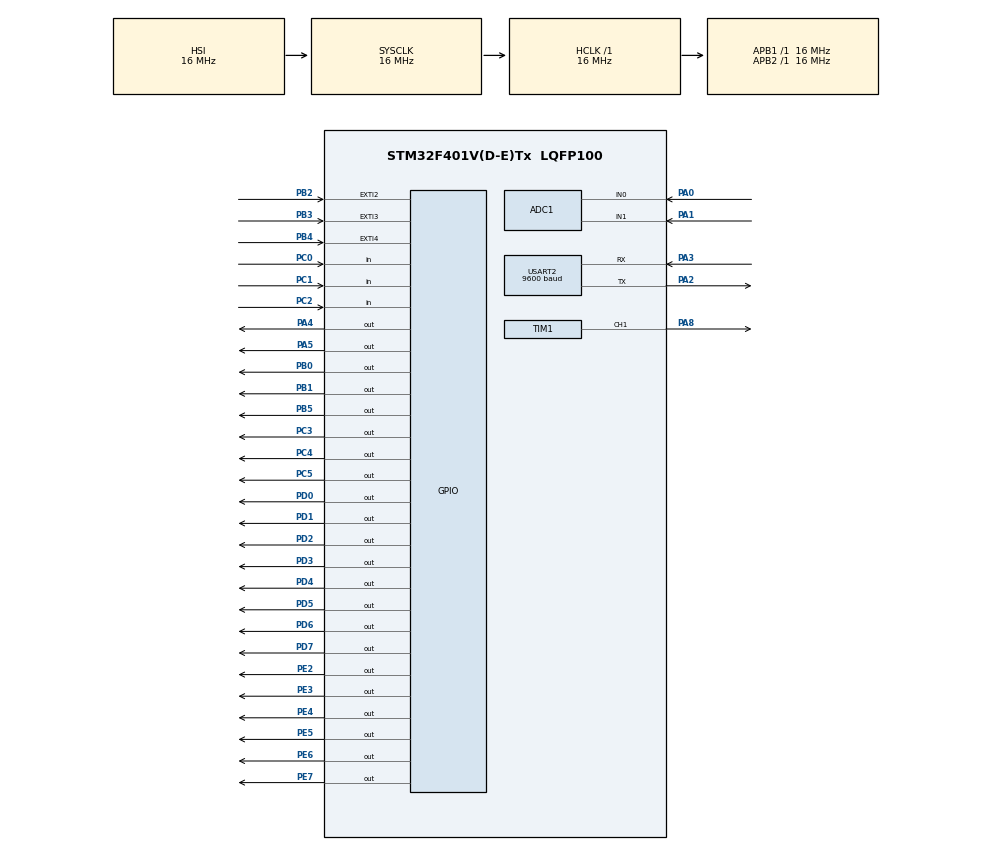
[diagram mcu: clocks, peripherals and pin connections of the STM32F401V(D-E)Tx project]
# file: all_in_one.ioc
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ADC1.Channel-0\#ChannelRegularConversion=ADC_CHANNEL_1
ADC1.NbrOfConversionFlag=1
ADC1.Rank-0\#ChannelRegularConversion=1
ADC1.SamplingTime-0\#ChannelRegularConversion=ADC_SAMPLETIME_3CYCLES
ADC1.master=1
Mcu.Family=STM32F4
Mcu.Name=STM32F401V(D-E)Tx
Mcu.Package=LQFP100
NVIC.EXTI2_IRQn=true\:0\:0\:false\:false\:true\:true\:true\:true
NVIC.EXTI3_IRQn=true\:0\:0\:false\:false\:true\:true\:true\:true
NVIC.EXTI4_IRQn=true\:0\:0\:false\:false\:true\:true\:true\:true
NVIC.PriorityGroup=NVIC_PRIORITYGROUP_4
NVIC.TIM2_IRQn=true\:0\:0\:false\:false\:true\:true\:true\:true
PA0-WKUP.Signal=ADCx_IN0
PA1.Signal=ADCx_IN1
PA13.Mode=Serial_Wire
PA13.Signal=SYS_JTMS-SWDIO
PA14.Mode=Serial_Wire
PA14.Signal=SYS_JTCK-SWCLK
PA2.Mode=Asynchronous
PA2.Signal=USART2_TX
PA3.Mode=Asynchronous
PA3.Signal=USART2_RX
PA4.Signal=GPIO_Output
PA5.Signal=GPIO_Output
PA8.Signal=S_TIM1_CH1
PB0.Signal=GPIO_Output
PB1.Signal=GPIO_Output
PB2.Signal=GPXTI2
PB3.Signal=GPXTI3
PB4.Signal=GPXTI4
PB5.Signal=GPIO_Output
PC0.Signal=GPIO_Input
PC1.Signal=GPIO_Input
PC2.Signal=GPIO_Input
PC3.Signal=GPIO_Output
PC4.Signal=GPIO_Output
PC5.Signal=GPIO_Output
PD0.Signal=GPIO_Output
PD1.Signal=GPIO_Output
PD2.Signal=GPIO_Output
PD3.Signal=GPIO_Output
PD4.Signal=GPIO_Output
PD5.Signal=GPIO_Output
PD6.Signal=GPIO_Output
PD7.Signal=GPIO_Output
PE2.Signal=GPIO_Output
PE3.Signal=GPIO_Output
PE4.Signal=GPIO_Output
PE5.Signal=GPIO_Output
PE6.Signal=GPIO_Output
PE7.Signal=GPIO_Output
ProjectManager.HeapSize=0x200
ProjectManager.StackSize=0x400
ProjectManager.TargetToolchain=STM32CubeIDE
RCC.AHBFreq_Value=16000000
RCC.APB1Freq_Value=16000000
RCC.APB2Freq_Value=16000000
RCC.CortexFreq_Value=16000000
RCC.HSE_VALUE=25000000
RCC.HSI_VALUE=16000000
RCC.LSE_VALUE=32768
RCC.SYSCLKFreq_VALUE=16000000
RCC.VCOOutputFreq_Value=192000000
SH.ADCx_IN0.0=ADC1_IN0,IN0
SH.ADCx_IN1.0=ADC1_IN1,IN1
SH.S_TIM1_CH1.0=TIM1_CH1,PWM Generation1 CH1
TIM1.Channel-PWM\ Generation1\ CH1=TIM_CHANNEL_1
TIM1.Prescaler=84
TIM2.Prescaler=8399
USART2.BaudRate=9600
USART2.VirtualMode=VM_ASYNC
VP_TIM2_VS_ClockSourceINT.Mode=Internal
board=custom

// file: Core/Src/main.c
#include "main.h"
#include "string.h"
#include <stdio.h>
#include <stdbool.h>
#include "FLASH_SECTOR_F4.h"
#include "lcd.h"
#include <inttypes.h>

#define temp_MIN 0x0807FF00
#define temp_MAX 0x0807FF20
#define alert_number 0x0807FF40

ADC_HandleTypeDef hadc1;
TIM_HandleTypeDef htim1;
TIM_HandleTypeDef htim2;
UART_HandleTypeDef huart2;

void SystemClock_Config(void);
static void MX_GPIO_Init(void);
static void MX_ADC1_Init(void);
static void MX_TIM1_Init(void);
static void MX_TIM2_Init(void);
static void MX_USART2_UART_Init(void);

extern ADC_HandleTypeDef hadc1;
extern TIM_HandleTypeDef htim1;
#define TEMP_MIN 18.0
#define TEMP_MAX 25.0

char msg[50];
uint32_t adcValue = 0;
uint8_t moteur_actif = 0;
uint8_t motor_counter = 0;
uint32_t currentTime;
uint32_t previousTime;
uint32_t led_green_Time = 0;
uint32_t BCD_Time = 0;
uint8_t counter = 0;
uint32_t start = 0;
uint16_t alert_compteur= 0;

bool led_green_state = false;
bool BCD_state = false;
bool BCD_buzz_state = false;

void write_temp_min (float temp){
	Flash_Write_NUM(temp_MIN,temp);
}
void write_temp_max (float temp){
	Flash_Write_NUM(temp_MAX,temp);
}
void write_alert_number (int num){
	Flash_Write_NUM(alert_number,num);
}

int read_alert_number (void){
	  int RxVal;
	  RxVal = Flash_Read_NUM(alert_number);
	  return RxVal;
}
float read_temp_min  (void){
	  float RxVal;
	  RxVal = Flash_Read_NUM(temp_MIN);
	  return RxVal;
}
float read_temp_max (void){
	  float RxVal;
	  RxVal = Flash_Read_NUM(temp_MAX);
	  return RxVal;
}

void setMotor(bool on) {
    if (on) {
        HAL_GPIO_WritePin(GPIOA, GPIO_PIN_4, GPIO_PIN_SET);
        __HAL_TIM_SET_COMPARE(&htim1, TIM_CHANNEL_1, 100);
    } else {
        HAL_GPIO_WritePin(GPIOA, GPIO_PIN_4, GPIO_PIN_RESET);
        __HAL_TIM_SET_COMPARE(&htim1, TIM_CHANNEL_1, 0);
    }
}

float read_temperature(void)
{
    uint32_t adc_val1 = 0;
    ADC_ChannelConfTypeDef sConfig = {0};

    sConfig.Channel = ADC_CHANNEL_1;
    sConfig.Rank = 1;
    sConfig.SamplingTime = ADC_SAMPLETIME_3CYCLES;

    if (HAL_ADC_ConfigChannel(&hadc1, &sConfig) != HAL_OK)
    {
        Error_Handler();
    }

    HAL_ADC_Start(&hadc1);
    HAL_ADC_PollForConversion(&hadc1, HAL_MAX_DELAY);
    adc_val1 = HAL_ADC_GetValue(&hadc1);
    HAL_ADC_Stop(&hadc1);

    float voltage = (adc_val1 * 5.0f) / 4095.0f;
    float temperature = voltage * 100.0f;

    return temperature;
}

void afficherLettreA(void)
{
    uint8_t segmentsActifs = 0x77;
    for (int i = 0; i < 7; i++) {
        if (segmentsActifs & (1 << i)) {
            HAL_GPIO_WritePin(GPIOD, GPIO_PIN_0 << i, GPIO_PIN_SET);
        } else {
            HAL_GPIO_WritePin(GPIOD, GPIO_PIN_0 << i, GPIO_PIN_RESET);
        }
    }
}

void eteindreAfficheur(void)
{
    for (int i = 0; i < 7; i++) {
        HAL_GPIO_WritePin(GPIOD, GPIO_PIN_0 << i, GPIO_PIN_RESET);
    }
}

uint32_t light_sensor(){
    ADC_ChannelConfTypeDef sConfig = {0};

    sConfig.Channel = ADC_CHANNEL_0;
    sConfig.Rank = 1;
    sConfig.SamplingTime = ADC_SAMPLETIME_3CYCLES;

    if (HAL_ADC_ConfigChannel(&hadc1, &sConfig) != HAL_OK)
    {
        Error_Handler();
    }

    HAL_ADC_Start(&hadc1);
    HAL_ADC_PollForConversion(&hadc1, HAL_MAX_DELAY);
    adcValue = HAL_ADC_GetValue(&hadc1);
    HAL_ADC_Stop(&hadc1);

    HAL_Delay(100);
    return adcValue;
}

int main(void)
{

  HAL_Init();
  SystemClock_Config();
  MX_GPIO_Init();
  MX_ADC1_Init();
  MX_TIM1_Init();
  MX_TIM2_Init();
  MX_USART2_UART_Init();
  HAL_TIM_PWM_Start(&htim1, TIM_CHANNEL_1);
  char msg[64];

  write_alert_number(0);
  write_temp_max(0);
  write_temp_min(999);

  LCD_Init();
  LCD_Set_Cursor(0, 0);
  LCD_Send_String("   Bienvenue");
  HAL_Delay(200);
  LCD_Init();
  LCD_Set_Cursor(0, 0);
  LCD_Send_String("                      ");
  float temps_max=0;
  float temps_min=0;

  while (1)
  {
	  HAL_Delay(100);
	  if (led_green_state){
		  LCD_Init();
		  LCD_Set_Cursor(2, 0);
		  LCD_Send_String("Personne detecté");
		  if (HAL_GetTick()-led_green_Time >= 300){
			  HAL_GPIO_TogglePin(GPIOB, GPIO_PIN_1);
			  led_green_state = false;
			  LCD_Init();
    		  LCD_Set_Cursor(0, 0);
    		  LCD_Send_String("\n                         ");
		  }
	  }

	  if(BCD_state){

		  if((HAL_GetTick() - start) > 300){
		  eteindreAfficheur();
		  }
		  if((HAL_GetTick() - start) > 600){
		  afficherLettreA();
		  start=HAL_GetTick();
		  }

	  }
  	  float temp = read_temperature();
   	  temps_max=read_temp_max();
  	  if ((temps_max)<temp){
  		  write_temp_max(temp);
  	  }
   	  temps_min=read_temp_min();
  	  if ((temps_min)>temp){
  		  write_temp_min(temp);
  	  }

  	  write_alert_number(alert_compteur);

  	  read_alert_number();
      LCD_Set_Cursor(2, 0);
      sprintf(msg, "Temperature: %.2f C\r\n", temp);
      LCD_Send_String(msg);

      if (temp >= TEMP_MAX ) {
    	  HAL_TIM_Base_Start_IT(&htim2);
      } else if (temp <= TEMP_MIN ) {
    	  HAL_TIM_Base_Stop_IT(&htim2);
    	  setMotor(false);
      }

      if(light_sensor() >= 1539){
      		  HAL_GPIO_WritePin(GPIOB, GPIO_PIN_5, GPIO_PIN_SET);
      	  }
	  else{
		  HAL_GPIO_WritePin(GPIOB, GPIO_PIN_5, GPIO_PIN_RESET);
	  }

  }
}

void SystemClock_Config(void)
{
  RCC_OscInitTypeDef RCC_OscInitStruct = {0};
  RCC_ClkInitTypeDef RCC_ClkInitStruct = {0};

  /** Configure the main internal regulator output voltage
  */
  __HAL_RCC_PWR_CLK_ENABLE();
  __HAL_PWR_VOLTAGESCALING_CONFIG(PWR_REGULATOR_VOLTAGE_SCALE2);

  /** Initializes the RCC Oscillators according to the specified parameters
  * in the RCC_OscInitTypeDef structure.
  */
  RCC_OscInitStruct.OscillatorType = RCC_OSCILLATORTYPE_HSI;
  RCC_OscInitStruct.HSIState = RCC_HSI_ON;
  RCC_OscInitStruct.HSICalibrationValue = RCC_HSICALIBRATION_DEFAULT;
  RCC_OscInitStruct.PLL.PLLState = RCC_PLL_NONE;
  if (HAL_RCC_OscConfig(&RCC_OscInitStruct) != HAL_OK)
  {
    Error_Handler();
  }

  /** Initializes the CPU, AHB and APB buses clocks
  */
  RCC_ClkInitStruct.ClockType = RCC_CLOCKTYPE_HCLK|RCC_CLOCKTYPE_SYSCLK
                              |RCC_CLOCKTYPE_PCLK1|RCC_CLOCKTYPE_PCLK2;
  RCC_ClkInitStruct.SYSCLKSource = RCC_SYSCLKSOURCE_HSI;
  RCC_ClkInitStruct.AHBCLKDivider = RCC_SYSCLK_DIV1;
  RCC_ClkInitStruct.APB1CLKDivider = RCC_HCLK_DIV1;
  RCC_ClkInitStruct.APB2CLKDivider = RCC_HCLK_DIV1;

  if (HAL_RCC_ClockConfig(&RCC_ClkInitStruct, FLASH_LATENCY_0) != HAL_OK)
  {
    Error_Handler();
  }
}

static void MX_ADC1_Init(void)
{
  ADC_ChannelConfTypeDef sConfig = {0};

  hadc1.Instance = ADC1;
  hadc1.Init.ClockPrescaler = ADC_CLOCK_SYNC_PCLK_DIV2;
  hadc1.Init.Resolution = ADC_RESOLUTION_12B;
  hadc1.Init.ScanConvMode = ENABLE;
  hadc1.Init.ContinuousConvMode = DISABLE;
  hadc1.Init.DiscontinuousConvMode = DISABLE;
  hadc1.Init.ExternalTrigConvEdge = ADC_EXTERNALTRIGCONVEDGE_NONE;
  hadc1.Init.ExternalTrigConv = ADC_SOFTWARE_START;
  hadc1.Init.DataAlign = ADC_DATAALIGN_RIGHT;
  hadc1.Init.NbrOfConversion = 2;
  hadc1.Init.DMAContinuousRequests = DISABLE;
  hadc1.Init.EOCSelection = ADC_EOC_SINGLE_CONV;
  if (HAL_ADC_Init(&hadc1) != HAL_OK)
  {
    Error_Handler();
  }

  /** Configure for the selected ADC regular channel its corresponding rank in the sequencer and its sample time.
  */
  // Channel 0 - Light Sensor (PA0)
  sConfig.Channel = ADC_CHANNEL_0;
  sConfig.Rank = 1;
  sConfig.SamplingTime = ADC_SAMPLETIME_3CYCLES;
  if (HAL_ADC_ConfigChannel(&hadc1, &sConfig) != HAL_OK)
  {
      Error_Handler();
  }

  // Channel 1 - Temperature Sensor (PA1)
  sConfig.Channel = ADC_CHANNEL_1;
  sConfig.Rank = 2;
  sConfig.SamplingTime = ADC_SAMPLETIME_3CYCLES;
  if (HAL_ADC_ConfigChannel(&hadc1, &sConfig) != HAL_OK)
  {
      Error_Handler();
  }

}

static void MX_TIM1_Init(void)
{

  TIM_MasterConfigTypeDef sMasterConfig = {0};
  TIM_OC_InitTypeDef sConfigOC = {0};
  TIM_BreakDeadTimeConfigTypeDef sBreakDeadTimeConfig = {0};

  htim1.Instance = TIM1;
  htim1.Init.Prescaler = 84;
  htim1.Init.CounterMode = TIM_COUNTERMODE_UP;
  htim1.Init.Period = 65535;
  htim1.Init.ClockDivision = TIM_CLOCKDIVISION_DIV1;
  htim1.Init.RepetitionCounter = 0;
  htim1.Init.AutoReloadPreload = TIM_AUTORELOAD_PRELOAD_DISABLE;
  if (HAL_TIM_PWM_Init(&htim1) != HAL_OK)
  {
    Error_Handler();
  }
  sMasterConfig.MasterOutputTrigger = TIM_TRGO_RESET;
  sMasterConfig.MasterSlaveMode = TIM_MASTERSLAVEMODE_DISABLE;
  if (HAL_TIMEx_MasterConfigSynchronization(&htim1, &sMasterConfig) != HAL_OK)
  {
    Error_Handler();
  }
  sConfigOC.OCMode = TIM_OCMODE_PWM1;
  sConfigOC.Pulse = 0;
  sConfigOC.OCPolarity = TIM_OCPOLARITY_HIGH;
  sConfigOC.OCNPolarity = TIM_OCNPOLARITY_HIGH;
  sConfigOC.OCFastMode = TIM_OCFAST_DISABLE;
  sConfigOC.OCIdleState = TIM_OCIDLESTATE_RESET;
  sConfigOC.OCNIdleState = TIM_OCNIDLESTATE_RESET;
  if (HAL_TIM_PWM_ConfigChannel(&htim1, &sConfigOC, TIM_CHANNEL_1) != HAL_OK)
  {
    Error_Handler();
  }
  sBreakDeadTimeConfig.OffStateRunMode = TIM_OSSR_DISABLE;
  sBreakDeadTimeConfig.OffStateIDLEMode = TIM_OSSI_DISABLE;
  sBreakDeadTimeConfig.LockLevel = TIM_LOCKLEVEL_OFF;
  sBreakDeadTimeConfig.DeadTime = 0;
  sBreakDeadTimeConfig.BreakState = TIM_BREAK_DISABLE;
  sBreakDeadTimeConfig.BreakPolarity = TIM_BREAKPOLARITY_HIGH;
  sBreakDeadTimeConfig.AutomaticOutput = TIM_AUTOMATICOUTPUT_DISABLE;
  if (HAL_TIMEx_ConfigBreakDeadTime(&htim1, &sBreakDeadTimeConfig) != HAL_OK)
  {
    Error_Handler();
  }

  HAL_TIM_MspPostInit(&htim1);
}

static void MX_TIM2_Init(void)
{

  TIM_ClockConfigTypeDef sClockSourceConfig = {0};
  TIM_MasterConfigTypeDef sMasterConfig = {0};

  htim2.Instance = TIM2;
  htim2.Init.Prescaler = 8399;
  htim2.Init.CounterMode = TIM_COUNTERMODE_UP;
  htim2.Init.Period = 999;
  htim2.Init.ClockDivision = TIM_CLOCKDIVISION_DIV1;
  htim2.Init.AutoReloadPreload = TIM_AUTORELOAD_PRELOAD_DISABLE;
  if (HAL_TIM_Base_Init(&htim2) != HAL_OK)
  {
    Error_Handler();
  }
  sClockSourceConfig.ClockSource = TIM_CLOCKSOURCE_INTERNAL;
  if (HAL_TIM_ConfigClockSource(&htim2, &sClockSourceConfig) != HAL_OK)
  {
    Error_Handler();
  }
  sMasterConfig.MasterOutputTrigger = TIM_TRGO_RESET;
  sMasterConfig.MasterSlaveMode = TIM_MASTERSLAVEMODE_DISABLE;
  if (HAL_TIMEx_MasterConfigSynchronization(&htim2, &sMasterConfig) != HAL_OK)
  {
    Error_Handler();
  }
}

static void MX_USART2_UART_Init(void)
{

  huart2.Instance = USART2;
  huart2.Init.BaudRate = 9600;
  huart2.Init.WordLength = UART_WORDLENGTH_8B;
  huart2.Init.StopBits = UART_STOPBITS_1;
  huart2.Init.Parity = UART_PARITY_NONE;
  huart2.Init.Mode = UART_MODE_TX_RX;
  huart2.Init.HwFlowCtl = UART_HWCONTROL_NONE;
  huart2.Init.OverSampling = UART_OVERSAMPLING_16;
  if (HAL_UART_Init(&huart2) != HAL_OK)
  {
    Error_Handler();
  }

}

static void MX_GPIO_Init(void)
{
  GPIO_InitTypeDef GPIO_InitStruct = {0};

  __HAL_RCC_GPIOE_CLK_ENABLE();
  __HAL_RCC_GPIOC_CLK_ENABLE();
  __HAL_RCC_GPIOA_CLK_ENABLE();
  __HAL_RCC_GPIOB_CLK_ENABLE();
  __HAL_RCC_GPIOD_CLK_ENABLE();

  /*Configure GPIO pin Output Level */
  HAL_GPIO_WritePin(GPIOE, GPIO_PIN_2|GPIO_PIN_3|GPIO_PIN_4|GPIO_PIN_5
                          |GPIO_PIN_6|GPIO_PIN_7, GPIO_PIN_RESET);

  /*Configure GPIO pin Output Level */
  HAL_GPIO_WritePin(GPIOC, GPIO_PIN_3|GPIO_PIN_4|GPIO_PIN_5, GPIO_PIN_RESET);

  /*Configure GPIO pin Output Level */
  HAL_GPIO_WritePin(GPIOA, GPIO_PIN_4|GPIO_PIN_5, GPIO_PIN_RESET);

  /*Configure GPIO pin Output Level */
  HAL_GPIO_WritePin(GPIOB, GPIO_PIN_0|GPIO_PIN_1|GPIO_PIN_5, GPIO_PIN_RESET);

  /*Configure GPIO pin Output Level */
  HAL_GPIO_WritePin(GPIOD, GPIO_PIN_0|GPIO_PIN_1|GPIO_PIN_2|GPIO_PIN_3
                          |GPIO_PIN_4|GPIO_PIN_5|GPIO_PIN_6|GPIO_PIN_7, GPIO_PIN_RESET);

  /*Configure GPIO pins : PE2 PE3 PE4 PE5
                           PE6 PE7 */
  GPIO_InitStruct.Pin = GPIO_PIN_2|GPIO_PIN_3|GPIO_PIN_4|GPIO_PIN_5
                          |GPIO_PIN_6|GPIO_PIN_7;
  GPIO_InitStruct.Mode = GPIO_MODE_OUTPUT_PP;
  GPIO_InitStruct.Pull = GPIO_NOPULL;
  GPIO_InitStruct.Speed = GPIO_SPEED_FREQ_LOW;
  HAL_GPIO_Init(GPIOE, &GPIO_InitStruct);

  /*Configure GPIO pins : PC0 PC1 PC2 */
  GPIO_InitStruct.Pin = GPIO_PIN_0|GPIO_PIN_1|GPIO_PIN_2;
  GPIO_InitStruct.Mode = GPIO_MODE_INPUT;
  GPIO_InitStruct.Pull = GPIO_NOPULL;
  HAL_GPIO_Init(GPIOC, &GPIO_InitStruct);

  /*Configure GPIO pins : PC3 PC4 PC5 */
  GPIO_InitStruct.Pin = GPIO_PIN_3|GPIO_PIN_4|GPIO_PIN_5;
  GPIO_InitStruct.Mode = GPIO_MODE_OUTPUT_PP;
  GPIO_InitStruct.Pull = GPIO_NOPULL;
  GPIO_InitStruct.Speed = GPIO_SPEED_FREQ_LOW;
  HAL_GPIO_Init(GPIOC, &GPIO_InitStruct);

  /*Configure GPIO pins : PB2 PB3 PB4 */
  GPIO_InitStruct.Pin = GPIO_PIN_2|GPIO_PIN_3|GPIO_PIN_4;
  GPIO_InitStruct.Mode = GPIO_MODE_IT_RISING;
  GPIO_InitStruct.Pull = GPIO_NOPULL;
  HAL_GPIO_Init(GPIOB, &GPIO_InitStruct);

  /*Configure GPIO pins : PA4 PA5 */
  GPIO_InitStruct.Pin = GPIO_PIN_4|GPIO_PIN_5;
  GPIO_InitStruct.Mode = GPIO_MODE_OUTPUT_PP;
  GPIO_InitStruct.Pull = GPIO_NOPULL;
  GPIO_InitStruct.Speed = GPIO_SPEED_FREQ_LOW;
  HAL_GPIO_Init(GPIOA, &GPIO_InitStruct);

  /*Configure GPIO pins : PB0 PB1 PB5 */
  GPIO_InitStruct.Pin = GPIO_PIN_0|GPIO_PIN_1|GPIO_PIN_5;
  GPIO_InitStruct.Mode = GPIO_MODE_OUTPUT_PP;
  GPIO_InitStruct.Pull = GPIO_NOPULL;
  GPIO_InitStruct.Speed = GPIO_SPEED_FREQ_LOW;
  HAL_GPIO_Init(GPIOB, &GPIO_InitStruct);

  /*Configure GPIO pins : PD0 PD1 PD2 PD3
                           PD4 PD5 PD6 PD7 */
  GPIO_InitStruct.Pin = GPIO_PIN_0|GPIO_PIN_1|GPIO_PIN_2|GPIO_PIN_3
                          |GPIO_PIN_4|GPIO_PIN_5|GPIO_PIN_6|GPIO_PIN_7;
  GPIO_InitStruct.Mode = GPIO_MODE_OUTPUT_PP;
  GPIO_InitStruct.Pull = GPIO_NOPULL;
  GPIO_InitStruct.Speed = GPIO_SPEED_FREQ_LOW;
  HAL_GPIO_Init(GPIOD, &GPIO_InitStruct);

  /* USER CODE BEGIN MX_GPIO_Init_2 */
  /* EXTI interrupt init*/
  HAL_NVIC_SetPriority(EXTI2_IRQn, 0, 0);
  HAL_NVIC_EnableIRQ(EXTI2_IRQn);

  HAL_NVIC_SetPriority(EXTI3_IRQn, 0, 0);
  HAL_NVIC_EnableIRQ(EXTI3_IRQn);

  HAL_NVIC_SetPriority(EXTI4_IRQn, 0, 0);
  HAL_NVIC_EnableIRQ(EXTI4_IRQn);
  /* USER CODE END MX_GPIO_Init_2 */
}

void HAL_GPIO_EXTI_Callback(uint16_t GPIO_Pin)
{
  /* Prevent unused argument(s) compilation warning */
  UNUSED(GPIO_Pin);
  /* NOTE: This function Should not be modified, when the callback is needed,
           the HAL_GPIO_EXTI_Callback could be implemented in the user file
   */

  	  currentTime = HAL_GetTick();
  	  // debounce for 5 ms
  	  if (currentTime - previousTime < 5) return;

      switch (GPIO_Pin)
      {

      	  case GPIO_PIN_2:

			  HAL_GPIO_TogglePin(GPIOD, GPIO_PIN_7);

			  afficherLettreA();
			  alert_compteur++;
			  BCD_state = !BCD_state;
			  if(!BCD_state){
				  eteindreAfficheur();
			  }

			  start = HAL_GetTick();
			  break;

          case GPIO_PIN_3:
        	  if(counter > 0){
        		  HAL_GPIO_WritePin(GPIOB, GPIO_PIN_0, GPIO_PIN_RESET);

        		  HAL_GPIO_TogglePin(GPIOB, GPIO_PIN_1);
        		  led_green_state = true;
        		  led_green_Time=HAL_GetTick();
				  counter--;
        	  }
              break;

          case GPIO_PIN_4:
        	  if (counter < 7){
        		  HAL_GPIO_TogglePin(GPIOB, GPIO_PIN_1);
        		  led_green_state = true;
        		  led_green_Time=HAL_GetTick();
        		  counter++;

        	  }
        	  else{
        		  HAL_GPIO_WritePin(GPIOB, GPIO_PIN_0, GPIO_PIN_SET);
        	  }
              break;

          default:
              break;
      }

      previousTime = currentTime;
}
void HAL_TIM_PeriodElapsedCallback(TIM_HandleTypeDef *htim)
{
    if(htim->Instance == TIM2)
    {
        motor_counter++;

        if (moteur_actif == 1 && motor_counter == 3)
        {
            setMotor(false);
            moteur_actif = 0;
            motor_counter = 0;
        }
        else if (moteur_actif == 0 && motor_counter == 1)
        {
            setMotor(true);
            moteur_actif = 1;
            motor_counter = 0;
        }
    }
}

void Error_Handler(void)
{
  /* USER CODE BEGIN Error_Handler_Debug */
  /* User can add his own implementation to report the HAL error return state */
  __disable_irq();
  while (1){}
}
